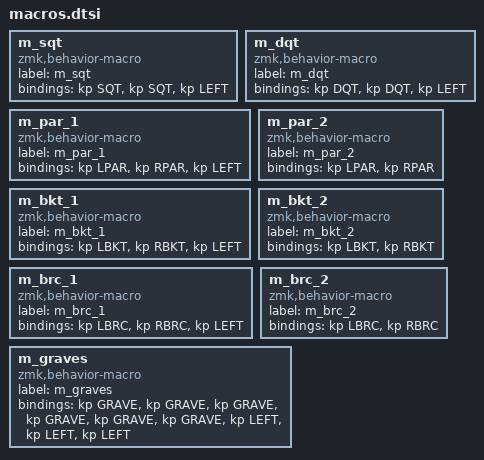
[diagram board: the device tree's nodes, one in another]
/* quotes */

m_sqt: m_sqt {
    compatible = "zmk,behavior-macro";
    label = "m_sqt";
    #binding-cells = <0>;
    bindings = <&kp SQT>, <&kp SQT>, <&kp LEFT>;
};

m_dqt: m_dqt {
    compatible = "zmk,behavior-macro";
    label = "m_dqt";
    #binding-cells = <0>;
    bindings = <&kp DQT>, <&kp DQT>, <&kp LEFT>;
};

/* parentheses */

m_par_1: m_par_1 {
    compatible = "zmk,behavior-macro";
    label = "m_par_1";
    #binding-cells = <0>;
    bindings = <&kp LPAR>, <&kp RPAR>, <&kp LEFT>;
};

m_par_2: m_par_2 {
    compatible = "zmk,behavior-macro";
    label = "m_par_2";
    #binding-cells = <0>;
    bindings = <&kp LPAR>, <&kp RPAR>;
};

/* brackets */

m_bkt_1: m_bkt_1 {
    compatible = "zmk,behavior-macro";
    label = "m_bkt_1";
    #binding-cells = <0>;
    bindings = <&kp LBKT>, <&kp RBKT>, <&kp LEFT>;
};

m_bkt_2: m_bkt_2 {
    compatible = "zmk,behavior-macro";
    label = "m_bkt_2";
    #binding-cells = <0>;
    bindings = <&kp LBKT>, <&kp RBKT>;
};

/* braces */

m_brc_1: m_brc_1 {
    compatible = "zmk,behavior-macro";
    label = "m_brc_1";
    #binding-cells = <0>;
    bindings = <&kp LBRC>, <&kp RBRC>, <&kp LEFT>;
};

m_brc_2: m_brc_2 {
    compatible = "zmk,behavior-macro";
    label = "m_brc_2";
    #binding-cells = <0>;
    bindings = <&kp LBRC>, <&kp RBRC>;
};

/* misc */

m_graves: m_graves {
    compatible = "zmk,behavior-macro";
    label = "m_graves";
    #binding-cells = <0>;
    bindings = <&kp GRAVE>, <&kp GRAVE>, <&kp GRAVE>, <&kp GRAVE>, <&kp GRAVE>, <&kp GRAVE>, <&kp LEFT>, <&kp LEFT>, <&kp LEFT>;
};
